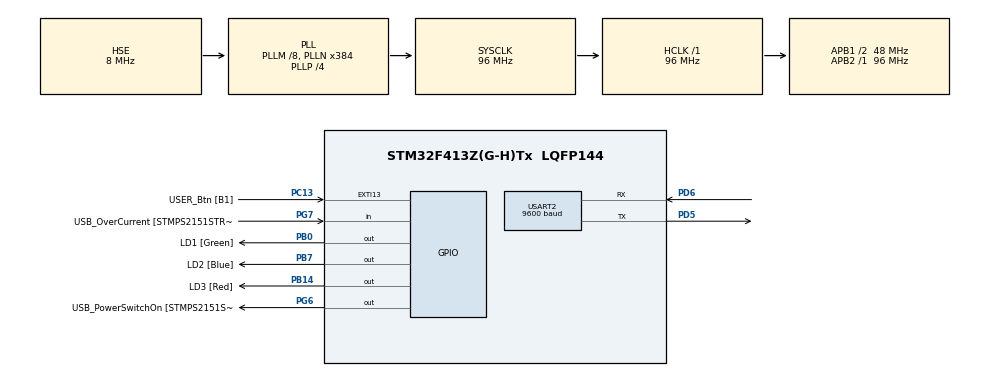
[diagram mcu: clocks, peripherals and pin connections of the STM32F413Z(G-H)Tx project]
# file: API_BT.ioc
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Mcu.Family=STM32F4
Mcu.Name=STM32F413Z(G-H)Tx
Mcu.Package=LQFP144
NVIC.EXTI15_10_IRQn=true\:0\:0\:false\:false\:true\:true\:true\:true
NVIC.PriorityGroup=NVIC_PRIORITYGROUP_4
NVIC.USART2_IRQn=true\:0\:0\:false\:false\:true\:true\:true\:true
PA13.GPIO_Label=TMS
PA13.Mode=Serial_Wire
PA13.Signal=SYS_JTMS-SWDIO
PA14.GPIO_Label=TCK
PA14.Mode=Serial_Wire
PA14.Signal=SYS_JTCK-SWCLK
PB0.GPIO_Label=LD1 [Green]
PB0.Signal=GPIO_Output
PB14.GPIO_Label=LD3 [Red]
PB14.Signal=GPIO_Output
PB3.GPIO_Label=SWO
PB3.Signal=SYS_JTDO-SWO
PB7.GPIO_Label=LD2 [Blue]
PB7.Signal=GPIO_Output
PC13.GPIO_Label=USER_Btn [B1]
PC13.Signal=GPXTI13
PC14-OSC32_IN.Mode=LSE-External-Oscillator
PC14-OSC32_IN.Signal=RCC_OSC32_IN
PC15-OSC32_OUT.Mode=LSE-External-Oscillator
PC15-OSC32_OUT.Signal=RCC_OSC32_OUT
PD5.Mode=Asynchronous
PD5.Signal=USART2_TX
PD6.Mode=Asynchronous
PD6.Signal=USART2_RX
PG6.GPIO_Label=USB_PowerSwitchOn [STMPS2151STR_EN]
PG6.Signal=GPIO_Output
PG7.GPIO_Label=USB_OverCurrent [STMPS2151STR_FAULT]
PG7.Signal=GPIO_Input
PH0\ -\ OSC_IN.GPIO_Label=MCO
PH0\ -\ OSC_IN.Mode=HSE-External-Clock-Source
PH0\ -\ OSC_IN.Signal=RCC_OSC_IN
PH1\ -\ OSC_OUT.Mode=HSE-External-Clock-Source
PH1\ -\ OSC_OUT.Signal=RCC_OSC_OUT
ProjectManager.HeapSize=0x200
ProjectManager.StackSize=0x400
ProjectManager.TargetToolchain=STM32CubeIDE
RCC.48MHZClocksFreq_Value=24000000
RCC.AHBFreq_Value=96000000
RCC.APB1CLKDivider=RCC_HCLK_DIV2
RCC.APB1Freq_Value=48000000
RCC.APB1TimFreq_Value=96000000
RCC.APB2Freq_Value=96000000
RCC.APB2TimFreq_Value=96000000
RCC.CortexFreq_Value=96000000
RCC.HCLKFreq_Value=96000000
RCC.HSE_VALUE=8000000
RCC.HSI_VALUE=16000000
RCC.PLLM=8
RCC.PLLMUL=RCC_PLL_MUL9
RCC.PLLN=384
RCC.PLLP=RCC_PLLP_DIV4
RCC.PLLQ=8
RCC.PLLSourceVirtual=RCC_PLLSOURCE_HSE
RCC.PRESCALERUSB=RCC_USBCLKSOURCE_PLL_DIV1_5
RCC.SYSCLKFreq_VALUE=96000000
RCC.SYSCLKSource=RCC_SYSCLKSOURCE_PLLCLK
RCC.SYSCLKSourceVirtual=RCC_SYSCLKSOURCE_PLLCLK
RCC.USBFreq_Value=48000000
RCC.VCOOutputFreq_Value=384000000
USART2.BaudRate=9600
USART2.VirtualMode=VM_ASYNC
board=NUCLEO-F413ZH

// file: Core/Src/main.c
/* USER CODE BEGIN Header */
/**
  ******************************************************************************
  * @file           : main.c
  * @brief          : Main program body
  ******************************************************************************
  * @attention
  *
  * Copyright (c) 2025 STMicroelectronics.
  * All rights reserved.
  *
  * This software is licensed under terms that can be found in the LICENSE file
  * in the root directory of this software component.
  * If no LICENSE file comes with this software, it is provided AS-IS.
  *
  ******************************************************************************
  */
/* USER CODE END Header */
#include "main.h"

/* USER CODE BEGIN Includes */
#include "API_BT.h"
/* USER CODE END Includes */

/* USER CODE BEGIN PD */
extern UART_HandleTypeDef huart2;
/* USER CODE END PD */

/* USER CODE BEGIN PV */
msj_t mensaje[]="Alarma Activada\r\n";
/* USER CODE END PV */

void SystemClock_Config(void);
static void MX_GPIO_Init(void);

int main(void)
{

  /* MCU Configuration--------------------------------------------------------*/

  /* Reset of all peripherals, Initializes the Flash interface and the Systick. */
  HAL_Init();

  /* Configure the system clock */
  SystemClock_Config();

  /* Initialize all configured peripherals */
  MX_GPIO_Init();
  MX_USART2_UART_Init();

  /* Infinite loop */
  while (1)
  {

    /* USER CODE BEGIN 3 */
	  HAL_GPIO_TogglePin(GPIOB, LD1_Pin);
	  HAL_Delay(200);
	  BT_TX(mensaje);
	 // HAL_UART_Transmit(&huart2, "12", 2, HAL_MAX_DELAY);
  }
  /* USER CODE END 3 */
}

void SystemClock_Config(void)
{
  RCC_OscInitTypeDef RCC_OscInitStruct = {0};
  RCC_ClkInitTypeDef RCC_ClkInitStruct = {0};

  /** Configure the main internal regulator output voltage
  */
  __HAL_RCC_PWR_CLK_ENABLE();
  __HAL_PWR_VOLTAGESCALING_CONFIG(PWR_REGULATOR_VOLTAGE_SCALE1);

  /** Initializes the RCC Oscillators according to the specified parameters
  * in the RCC_OscInitTypeDef structure.
  */
  RCC_OscInitStruct.OscillatorType = RCC_OSCILLATORTYPE_HSE;
  RCC_OscInitStruct.HSEState = RCC_HSE_BYPASS;
  RCC_OscInitStruct.PLL.PLLState = RCC_PLL_ON;
  RCC_OscInitStruct.PLL.PLLSource = RCC_PLLSOURCE_HSE;
  RCC_OscInitStruct.PLL.PLLM = 8;
  RCC_OscInitStruct.PLL.PLLN = 384;
  RCC_OscInitStruct.PLL.PLLP = RCC_PLLP_DIV4;
  RCC_OscInitStruct.PLL.PLLQ = 8;
  RCC_OscInitStruct.PLL.PLLR = 2;
  if (HAL_RCC_OscConfig(&RCC_OscInitStruct) != HAL_OK)
  {
    Error_Handler();
  }

  /** Initializes the CPU, AHB and APB buses clocks
  */
  RCC_ClkInitStruct.ClockType = RCC_CLOCKTYPE_HCLK|RCC_CLOCKTYPE_SYSCLK
                              |RCC_CLOCKTYPE_PCLK1|RCC_CLOCKTYPE_PCLK2;
  RCC_ClkInitStruct.SYSCLKSource = RCC_SYSCLKSOURCE_PLLCLK;
  RCC_ClkInitStruct.AHBCLKDivider = RCC_SYSCLK_DIV1;
  RCC_ClkInitStruct.APB1CLKDivider = RCC_HCLK_DIV2;
  RCC_ClkInitStruct.APB2CLKDivider = RCC_HCLK_DIV1;

  if (HAL_RCC_ClockConfig(&RCC_ClkInitStruct, FLASH_LATENCY_3) != HAL_OK)
  {
    Error_Handler();
  }
}

static void MX_GPIO_Init(void)
{
  GPIO_InitTypeDef GPIO_InitStruct = {0};

  /* GPIO Ports Clock Enable */
  __HAL_RCC_GPIOC_CLK_ENABLE();
  __HAL_RCC_GPIOH_CLK_ENABLE();
  __HAL_RCC_GPIOB_CLK_ENABLE();
  __HAL_RCC_GPIOG_CLK_ENABLE();
  __HAL_RCC_GPIOA_CLK_ENABLE();
  __HAL_RCC_GPIOD_CLK_ENABLE();

  /*Configure GPIO pin Output Level */
  HAL_GPIO_WritePin(GPIOB, LD1_Pin|LD3_Pin|LD2_Pin, GPIO_PIN_RESET);

  /*Configure GPIO pin Output Level */
  HAL_GPIO_WritePin(USB_PowerSwitchOn_GPIO_Port, USB_PowerSwitchOn_Pin, GPIO_PIN_RESET);

  /*Configure GPIO pin : USER_Btn_Pin */
  GPIO_InitStruct.Pin = USER_Btn_Pin;
  GPIO_InitStruct.Mode = GPIO_MODE_IT_RISING;
  GPIO_InitStruct.Pull = GPIO_NOPULL;
  HAL_GPIO_Init(USER_Btn_GPIO_Port, &GPIO_InitStruct);

  /*Configure GPIO pins : LD1_Pin LD3_Pin LD2_Pin */
  GPIO_InitStruct.Pin = LD1_Pin|LD3_Pin|LD2_Pin;
  GPIO_InitStruct.Mode = GPIO_MODE_OUTPUT_PP;
  GPIO_InitStruct.Pull = GPIO_NOPULL;
  GPIO_InitStruct.Speed = GPIO_SPEED_FREQ_LOW;
  HAL_GPIO_Init(GPIOB, &GPIO_InitStruct);

  /*Configure GPIO pin : USB_PowerSwitchOn_Pin */
  GPIO_InitStruct.Pin = USB_PowerSwitchOn_Pin;
  GPIO_InitStruct.Mode = GPIO_MODE_OUTPUT_PP;
  GPIO_InitStruct.Pull = GPIO_NOPULL;
  GPIO_InitStruct.Speed = GPIO_SPEED_FREQ_LOW;
  HAL_GPIO_Init(USB_PowerSwitchOn_GPIO_Port, &GPIO_InitStruct);

  /*Configure GPIO pin : USB_OverCurrent_Pin */
  GPIO_InitStruct.Pin = USB_OverCurrent_Pin;
  GPIO_InitStruct.Mode = GPIO_MODE_INPUT;
  GPIO_InitStruct.Pull = GPIO_NOPULL;
  HAL_GPIO_Init(USB_OverCurrent_GPIO_Port, &GPIO_InitStruct);

  /* EXTI interrupt init*/
  HAL_NVIC_SetPriority(EXTI15_10_IRQn, 0, 0);
  HAL_NVIC_EnableIRQ(EXTI15_10_IRQn);

}

void Error_Handler(void)
{
  __disable_irq();
  while (1)
  {
  }
}
